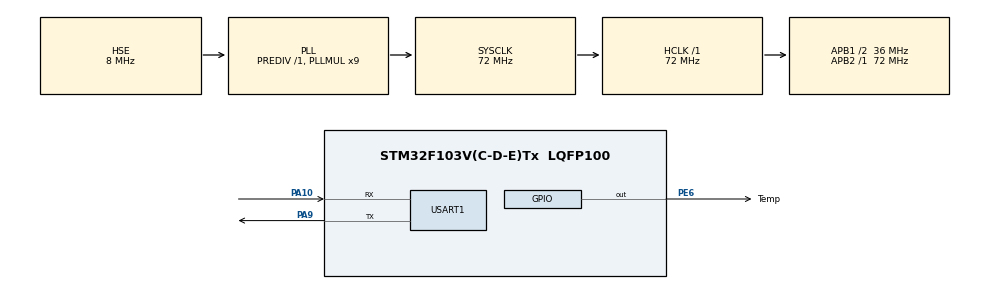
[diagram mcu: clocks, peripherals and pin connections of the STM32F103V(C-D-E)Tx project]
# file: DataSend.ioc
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FREERTOS.BinarySemaphores01=getTempStart,Dynamic,NULL,Depleted
FREERTOS.Queues01=sensorDataQueue,10,uint8_t,0,Dynamic,NULL,NULL;tempQueue,1,float,0,Dynamic,NULL,NULL
FREERTOS.Tasks01=startTask,24,128,StartDefaultTask,Default,NULL,Dynamic,NULL,NULL;getTemp,16,128,getTempTask,As weak,NULL,Dynamic,NULL,NULL;generateTlvData,8,128,generateTlvDataTask,As weak,NULL,Dynamic,NULL,NULL
FREERTOS.Timers01=getTempTimer,getTempTimerCallback,osTimerPeriodic,As weak,NULL,Dynamic,NULL
Mcu.Family=STM32F1
Mcu.Name=STM32F103V(C-D-E)Tx
Mcu.Package=LQFP100
NVIC.PriorityGroup=NVIC_PRIORITYGROUP_4
NVIC.TIM7_IRQn=true\:15\:0\:false\:false\:true\:false\:false\:true\:true
NVIC.TimeBase=TIM7_IRQn
NVIC.TimeBaseIP=TIM7
OSC_IN.Mode=HSE-External-Oscillator
OSC_IN.Signal=RCC_OSC_IN
OSC_OUT.Mode=HSE-External-Oscillator
OSC_OUT.Signal=RCC_OSC_OUT
PA10.Mode=Asynchronous
PA10.Signal=USART1_RX
PA13.Mode=JTAG_5_pins
PA13.Signal=SYS_JTMS-SWDIO
PA14.Mode=JTAG_5_pins
PA14.Signal=SYS_JTCK-SWCLK
PA15.Mode=JTAG_5_pins
PA15.Signal=SYS_JTDI
PA9.Mode=Asynchronous
PA9.Signal=USART1_TX
PB10.Signal=USART3_TX
PB3.Mode=JTAG_5_pins
PB3.Signal=SYS_JTDO-TRACESWO
PB4.Mode=JTAG_5_pins
PB4.Signal=SYS_NJTRST
PE6.GPIO_Label=Temp
PE6.Signal=GPIO_Output
ProjectManager.HeapSize=0x200
ProjectManager.StackSize=0x400
ProjectManager.TargetToolchain=MDK-ARM V5.32
RCC.AHBFreq_Value=72000000
RCC.APB1CLKDivider=RCC_HCLK_DIV2
RCC.APB1Freq_Value=36000000
RCC.APB1TimFreq_Value=72000000
RCC.APB2Freq_Value=72000000
RCC.APB2TimFreq_Value=72000000
RCC.HCLKFreq_Value=72000000
RCC.PLLMUL=RCC_PLL_MUL9
RCC.PLLSourceVirtual=RCC_PLLSOURCE_HSE
RCC.SYSCLKFreq_VALUE=72000000
RCC.SYSCLKSource=RCC_SYSCLKSOURCE_PLLCLK
RCC.USBFreq_Value=72000000
USART1.VirtualMode=VM_ASYNC
VP_FREERTOS_VS_CMSIS_V2.Mode=CMSIS_V2
VP_SYS_VS_tim7.Mode=TIM7
board=custom

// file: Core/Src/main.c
/* USER CODE BEGIN Header */
/**
 ******************************************************************************
 * @file           : main.c
 * @brief          : Main program body
 ******************************************************************************
 * @attention
 *
 * Copyright (c) 2026 STMicroelectronics.
 * All rights reserved.
 *
 * This software is licensed under terms that can be found in the LICENSE file
 * in the root directory of this software component.
 * If no LICENSE file comes with this software, it is provided AS-IS.
 *
 ******************************************************************************
 */
/* USER CODE END Header */
#include "main.h"
#include "cmsis_os.h"

/* USER CODE BEGIN Includes */
#include "process.h"
#include <stdio.h>
#include "core_delay.h"
#include "timers.h"
/* USER CODE END Includes */

UART_HandleTypeDef huart1;

/* Definitions for startTask */
osThreadId_t startTaskHandle;
const osThreadAttr_t startTask_attributes = {
    .name = "startTask",
    .stack_size = 128 * 4,
    .priority = (osPriority_t)osPriorityNormal,
};
/* Definitions for getTemp */
osThreadId_t getTempHandle;
const osThreadAttr_t getTemp_attributes = {
    .name = "getTemp",
    .stack_size = 128 * 4,
    .priority = (osPriority_t)osPriorityBelowNormal,
};
/* Definitions for generateTlvData */
osThreadId_t generateTlvDataHandle;
const osThreadAttr_t generateTlvData_attributes = {
    .name = "generateTlvData",
    .stack_size = 128 * 4,
    .priority = (osPriority_t)osPriorityLow,
};
/* Definitions for sensorDataQueue */
osMessageQueueId_t sensorDataQueueHandle;
const osMessageQueueAttr_t sensorDataQueue_attributes = {
    .name = "sensorDataQueue"};
/* Definitions for tempQueue */
osMessageQueueId_t tempQueueHandle;
const osMessageQueueAttr_t tempQueue_attributes = {
    .name = "tempQueue"};
/* Definitions for getTempTimer */
osTimerId_t getTempTimerHandle;
const osTimerAttr_t getTempTimer_attributes = {
    .name = "getTempTimer"};
/* Definitions for getTempStart */
osSemaphoreId_t getTempStartHandle;
const osSemaphoreAttr_t getTempStart_attributes = {
    .name = "getTempStart"};

void SystemClock_Config(void);
static void MX_GPIO_Init(void);
static void MX_USART1_UART_Init(void);
void StartDefaultTask(void *argument);
void getTempTask(void *argument);
void generateTlvDataTask(void *argument);
void getTempTimerCallback(void *argument);

int main(void)
{

    /* MCU Configuration--------------------------------------------------------*/

    /* Reset of all peripherals, Initializes the Flash interface and the Systick. */
    HAL_Init();

    /* Configure the system clock */
    SystemClock_Config();

    /* USER CODE BEGIN SysInit */
    SystemCoreClockUpdate();
    /* USER CODE END SysInit */

    /* Initialize all configured peripherals */
    MX_GPIO_Init();
    MX_USART1_UART_Init();
    /* USER CODE BEGIN 2 */
    // printf("sys tick %ul", SystemCoreClock);
    CPU_TS_TmrInit();
    deviceInit();
    /* USER CODE END 2 */

    /* Init scheduler */
    osKernelInitialize();

    /* Create the semaphores(s) */
    /* creation of getTempStart */
    getTempStartHandle = osSemaphoreNew(1, 0, &getTempStart_attributes);

    /* Create the timer(s) */
    /* creation of getTempTimer */
    getTempTimerHandle = osTimerNew(getTempTimerCallback, osTimerPeriodic, NULL, &getTempTimer_attributes);

    /* Create the queue(s) */
    /* creation of sensorDataQueue */
    sensorDataQueueHandle = osMessageQueueNew(10, sizeof(uint8_t), &sensorDataQueue_attributes);

    /* creation of tempQueue */
    tempQueueHandle = osMessageQueueNew(20, sizeof(float), &tempQueue_attributes);

    /* Create the thread(s) */
    /* creation of startTask */
    startTaskHandle = osThreadNew(StartDefaultTask, NULL, &startTask_attributes);

    /* creation of getTemp */
    getTempHandle = osThreadNew(getTempTask, NULL, &getTemp_attributes);

    /* creation of generateTlvData */
    generateTlvDataHandle = osThreadNew(generateTlvDataTask, NULL, &generateTlvData_attributes);

    /* Start scheduler */
    osKernelStart();

    /* We should never get here as control is now taken by the scheduler */

    /* Infinite loop */
    while (1)
    {

        /* USER CODE BEGIN 3 */
        //		OneWire_Delay_ms(1000);
    }
    /* USER CODE END 3 */
}

void SystemClock_Config(void)
{
    RCC_OscInitTypeDef RCC_OscInitStruct = {0};
    RCC_ClkInitTypeDef RCC_ClkInitStruct = {0};

    /** Initializes the RCC Oscillators according to the specified parameters
     * in the RCC_OscInitTypeDef structure.
     */
    RCC_OscInitStruct.OscillatorType = RCC_OSCILLATORTYPE_HSE;
    RCC_OscInitStruct.HSEState = RCC_HSE_ON;
    RCC_OscInitStruct.HSEPredivValue = RCC_HSE_PREDIV_DIV1;
    RCC_OscInitStruct.HSIState = RCC_HSI_ON;
    RCC_OscInitStruct.PLL.PLLState = RCC_PLL_ON;
    RCC_OscInitStruct.PLL.PLLSource = RCC_PLLSOURCE_HSE;
    RCC_OscInitStruct.PLL.PLLMUL = RCC_PLL_MUL9;
    if (HAL_RCC_OscConfig(&RCC_OscInitStruct) != HAL_OK)
    {
        Error_Handler();
    }

    /** Initializes the CPU, AHB and APB buses clocks
     */
    RCC_ClkInitStruct.ClockType = RCC_CLOCKTYPE_HCLK | RCC_CLOCKTYPE_SYSCLK | RCC_CLOCKTYPE_PCLK1 | RCC_CLOCKTYPE_PCLK2;
    RCC_ClkInitStruct.SYSCLKSource = RCC_SYSCLKSOURCE_PLLCLK;
    RCC_ClkInitStruct.AHBCLKDivider = RCC_SYSCLK_DIV1;
    RCC_ClkInitStruct.APB1CLKDivider = RCC_HCLK_DIV2;
    RCC_ClkInitStruct.APB2CLKDivider = RCC_HCLK_DIV1;

    if (HAL_RCC_ClockConfig(&RCC_ClkInitStruct, FLASH_LATENCY_2) != HAL_OK)
    {
        Error_Handler();
    }
}

static void MX_USART1_UART_Init(void)
{

    huart1.Instance = USART1;
    huart1.Init.BaudRate = 115200;
    huart1.Init.WordLength = UART_WORDLENGTH_8B;
    huart1.Init.StopBits = UART_STOPBITS_1;
    huart1.Init.Parity = UART_PARITY_NONE;
    huart1.Init.Mode = UART_MODE_TX_RX;
    huart1.Init.HwFlowCtl = UART_HWCONTROL_NONE;
    huart1.Init.OverSampling = UART_OVERSAMPLING_16;
    if (HAL_UART_Init(&huart1) != HAL_OK)
    {
        Error_Handler();
    }
}

static void MX_GPIO_Init(void)
{
    GPIO_InitTypeDef GPIO_InitStruct = {0};

    /* GPIO Ports Clock Enable */
    __HAL_RCC_GPIOE_CLK_ENABLE();
    __HAL_RCC_GPIOB_CLK_ENABLE();
    __HAL_RCC_GPIOA_CLK_ENABLE();

    /*Configure GPIO pin Output Level */
    HAL_GPIO_WritePin(Temp_GPIO_Port, Temp_Pin, GPIO_PIN_RESET);

    /*Configure GPIO pin : Temp_Pin */
    GPIO_InitStruct.Pin = Temp_Pin;
    GPIO_InitStruct.Mode = GPIO_MODE_OUTPUT_PP;
    GPIO_InitStruct.Pull = GPIO_NOPULL;
    GPIO_InitStruct.Speed = GPIO_SPEED_FREQ_LOW;
    HAL_GPIO_Init(Temp_GPIO_Port, &GPIO_InitStruct);

    /*Configure GPIO pin : PB10 */
    GPIO_InitStruct.Pin = GPIO_PIN_10;
    GPIO_InitStruct.Mode = GPIO_MODE_AF_PP;
    GPIO_InitStruct.Speed = GPIO_SPEED_FREQ_HIGH;
    HAL_GPIO_Init(GPIOB, &GPIO_InitStruct);

}

/* USER CODE BEGIN 4 */
int fputc(int ch, FILE *f)
{
    HAL_UART_Transmit(&huart1, (unsigned char *)&ch, 1, 0xFFFF);
    return (ch);
}

int fgetc(FILE *f)
{
    int ch;
    while (__HAL_UART_GET_FLAG(&huart1, UART_FLAG_RXNE) == RESET)
        ;
    HAL_UART_Receive(&huart1, (unsigned char *)&ch, 1, 0xFFFF);
    return (ch);
}
/* USER CODE END 4 */

void StartDefaultTask(void *argument)
{
    /* USER CODE BEGIN 5 */
    osTimerStart(getTempTimerHandle, 2000);

    /* Infinite loop */
    for (;;)
    {
        osDelay(1);
    }
    /* USER CODE END 5 */
}

__weak void getTempTask(void *argument)
{
    for (;;)
    {
        osDelay(1);
    }
}

__weak void generateTlvDataTask(void *argument)
{
    for (;;)
    {
        osDelay(1);
    }
}

/* getTempTimerCallback function */
__weak void getTempTimerCallback(void *argument)
{
}

void HAL_TIM_PeriodElapsedCallback(TIM_HandleTypeDef *htim)
{
    if (htim->Instance == TIM7)
    {
        HAL_IncTick();
    }
}

void Error_Handler(void)
{
    __disable_irq();
    while (1)
    {
    }
}
